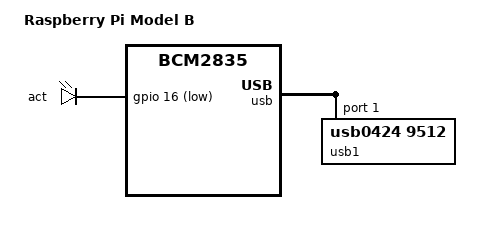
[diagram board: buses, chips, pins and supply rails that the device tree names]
/dts-v1/;
#include "bcm2835.dtsi"
#include "bcm2835-rpi.dtsi"

/ {
	compatible = "raspberrypi,model-b", "brcm,bcm2835";
	model = "Raspberry Pi Model B";

	aliases {
		ethernet = &ethernet;
	};

	leds {
		act {
			gpios = <&gpio 16 1>;
		};
	};
};

&gpio {
	pinctrl-0 = <&gpioout &alt0 &alt3>;
};

&usb {
	usb1@1 {
		compatible = "usb0424,9512";
		reg = <01>;
		#address-cells = <1>;
		#size-cells = <0>;

		ethernet: usbether@1 {
			compatible = "usb0424,ec00";
			reg = <01>;
		};
	};
};
